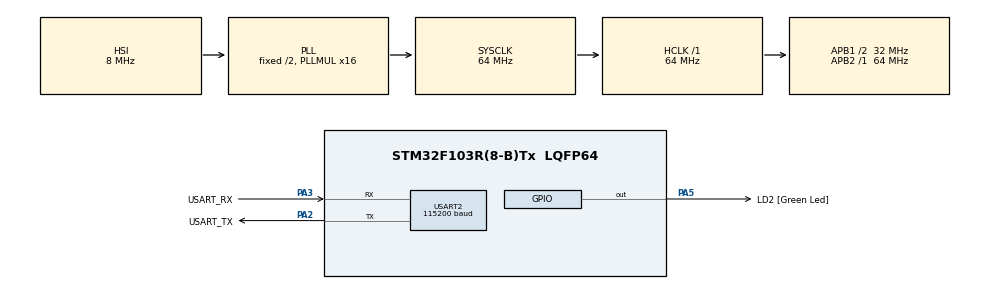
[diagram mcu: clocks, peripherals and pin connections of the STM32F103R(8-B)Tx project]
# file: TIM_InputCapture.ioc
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Mcu.Family=STM32F1
Mcu.Name=STM32F103R(8-B)Tx
Mcu.Package=LQFP64
NVIC.PriorityGroup=NVIC_PRIORITYGROUP_4
NVIC.TIM2_IRQn=true\:1\:0\:false\:false\:true\:true\:true\:true
PA0-WKUP.GPIO_Label=IC_IN
PA0-WKUP.GPIO_PuPd=GPIO_NOPULL
PA0-WKUP.Signal=S_TIM2_CH1_ETR
PA13.GPIO_Label=TMS
PA13.Mode=Serial_Wire
PA13.Signal=SYS_JTMS-SWDIO
PA14.GPIO_Label=TCK
PA14.Mode=Serial_Wire
PA14.Signal=SYS_JTCK-SWCLK
PA2.GPIO_Label=USART_TX
PA2.GPIO_Mode=GPIO_MODE_AF_PP
PA2.GPIO_PuPd=GPIO_NOPULL
PA2.GPIO_Speed=GPIO_SPEED_FREQ_LOW
PA2.Mode=Asynchronous
PA2.Signal=USART2_TX
PA3.GPIO_Label=USART_RX
PA3.GPIO_PuPd=GPIO_NOPULL
PA3.GPIO_Speed=GPIO_SPEED_FREQ_LOW
PA3.Mode=Asynchronous
PA3.Signal=USART2_RX
PA5.GPIO_Label=LD2 [Green Led]
PA5.GPIO_ModeDefaultOutputPP=GPIO_MODE_OUTPUT_PP
PA5.GPIO_PuPd=GPIO_NOPULL
PA5.GPIO_Speed=GPIO_SPEED_FREQ_LOW
PA5.Signal=GPIO_Output
PA6.GPIO_Label=TEST_PWM
PA6.GPIO_Speed=GPIO_SPEED_FREQ_HIGH
PA6.Signal=TIM3_CH1
PB3.GPIO_Label=SWO
PB3.Signal=SYS_JTDO-TRACESWO
PC14-OSC32_IN.Mode=LSE-External-Oscillator
PC14-OSC32_IN.Signal=RCC_OSC32_IN
PC15-OSC32_OUT.Mode=LSE-External-Oscillator
PC15-OSC32_OUT.Signal=RCC_OSC32_OUT
PD0-OSC_IN.Mode=HSE-External-Clock-Source
PD0-OSC_IN.Signal=RCC_OSC_IN
PD1-OSC_OUT.Mode=HSE-External-Clock-Source
PD1-OSC_OUT.Signal=RCC_OSC_OUT
ProjectManager.HeapSize=0x200
ProjectManager.StackSize=0x400
ProjectManager.TargetToolchain=STM32CubeIDE
RCC.AHBFreq_Value=64000000
RCC.APB1CLKDivider=RCC_HCLK_DIV2
RCC.APB1Freq_Value=32000000
RCC.APB1TimFreq_Value=64000000
RCC.APB2Freq_Value=64000000
RCC.APB2TimFreq_Value=64000000
RCC.HCLKFreq_Value=64000000
RCC.PLLMUL=RCC_PLL_MUL16
RCC.RTCClockSelection=RCC_RTCCLKSOURCE_LSE
RCC.SYSCLKFreq_VALUE=64000000
RCC.SYSCLKSource=RCC_SYSCLKSOURCE_PLLCLK
RCC.USBFreq_Value=64000000
TIM2.Channel=TIM_CHANNEL_1
TIM2.Period=65535
TIM2.Prescaler=63
TIM3.Channel-PWM Generation1 CH1=TIM_CHANNEL_1
TIM3.Period=9999
TIM3.Prescaler=63
TIM3.Pulse-PWM Generation1 CH1=5000
USART2.BaudRate=115200
USART2.VirtualMode=VM_ASYNC
board=NUCLEO-F103RB

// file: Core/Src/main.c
/* USER CODE BEGIN Header */
/**
 ******************************************************************************
 * @file           : main.c
 * @brief          : Main program body
 ******************************************************************************
 * @attention
 *
 * Copyright (c) 2026 STMicroelectronics.
 * All rights reserved.
 *
 * This software is licensed under terms that can be found in the LICENSE file
 * in the root directory of this software component.
 * If no LICENSE file comes with this software, it is provided AS-IS.
 *
 ******************************************************************************
 */
/**
 * 06_TIM_InputCapture  —  [계층: HAL]  TIM2 입력 캡처로 주파수 측정
 *
 * 동작
 *   - TIM3_CH1(PA6, 'D12')이 100Hz/50% PWM 테스트 신호를 출력한다.
 *   - TIM2_CH1(PA0, 'A0')이 상승 에지마다 CNT 값을 CCR1 에 래치(캡처)한다.
 *   - 연속된 두 캡처 값의 차 = 신호 주기(카운트) -> 주파수 계산 후 USART2(115200)로 0.5초마다 출력.
 *
 * 배선: PA6(D12) ---- 점퍼선 ---- PA0(A0)   (다른 신호를 측정하려면 PA0 에 연결)
 *
 * 측정 범위 계산
 *   TIM2 카운터 클럭 = 64MHz/64 = 1MHz (1us 분해능), 카운터 16비트(ARR=0xFFFF)
 *   최저 측정 주파수 = 1MHz/65536 = 약 15.3Hz,  주기 차 계산은 uint16_t 뺄셈으로 오버플로 1회를 자동 처리
 *
 * ISR vs 콜백
 *   TIM2_IRQHandler (stm32f1xx_it.c, 진짜 ISR) -> HAL_TIM_IRQHandler()
 *     -> HAL_TIM_IC_CaptureCallback() (이 파일)  : SR.CC1IF 발생 시 호출, ISR 문맥이므로 짧게 처리
 */
/* USER CODE END Header */
#include "main.h"

/* USER CODE BEGIN Includes */
#include <stdio.h>
#include <string.h>
/* USER CODE END Includes */

TIM_HandleTypeDef htim2;     /* 입력 캡처 */
TIM_HandleTypeDef htim3;     /* 테스트용 PWM */
UART_HandleTypeDef huart2;

/* USER CODE BEGIN PV */
static volatile uint16_t period_ticks;   /* 콜백에서 계산한 마지막 주기 [us] */
static volatile uint8_t  have_sample;    /* 마지막 출력 이후 새 캡처가 있었는가 */
static uint16_t last_capture;
static uint8_t  first_edge = 1;
/* USER CODE END PV */

void SystemClock_Config(void);
static void MX_GPIO_Init(void);
static void MX_TIM2_Init(void);
static void MX_TIM3_Init(void);
static void MX_USART2_UART_Init(void);

int main(void)
{

  /* USER CODE BEGIN 1 */
  char msg[64];
  /* USER CODE END 1 */

  /* MCU Configuration--------------------------------------------------------*/

  /* Reset of all peripherals, Initializes the Flash interface and the Systick. */
  HAL_Init();

  /* Configure the system clock */
  SystemClock_Config();

  /* Initialize all configured peripherals */
  MX_GPIO_Init();
  MX_TIM2_Init();
  MX_TIM3_Init();
  MX_USART2_UART_Init();
  /* USER CODE BEGIN 2 */
  /* TIM3_CH1 = PA6 테스트 PWM 시작: CCER.CC1E=1, CR1.CEN=1 */
  if (HAL_TIM_PWM_Start(&htim3, TIM_CHANNEL_1) != HAL_OK) Error_Handler();

  /* TIM2_CH1 입력 캡처 시작: DIER.CC1IE=1, CCER.CC1E=1, CR1.CEN=1 */
  if (HAL_TIM_IC_Start_IT(&htim2, TIM_CHANNEL_1) != HAL_OK) Error_Handler();
  /* USER CODE END 2 */

  /* Infinite loop */
  while (1)
  {

    /* USER CODE BEGIN 3 */
    HAL_Delay(500);

    /* ISR 과 공유하는 변수를 일관되게 복사하기 위해 잠깐 인터럽트를 막는다 */
    __disable_irq();
    uint16_t p = period_ticks;
    uint8_t ok = have_sample;
    have_sample = 0;
    __enable_irq();

    int n;
    if (ok && p != 0)
        n = snprintf(msg, sizeof msg, "period=%u us  freq=%lu Hz\r\n", (unsigned)p, (unsigned long)(1000000UL / p));
    else
        n = snprintf(msg, sizeof msg, "no signal on PA0\r\n");
    HAL_UART_Transmit(&huart2, (uint8_t *)msg, (uint16_t)n, 100);
  }
  /* USER CODE END 3 */
}

void SystemClock_Config(void)
{
  RCC_OscInitTypeDef RCC_OscInitStruct = {0};
  RCC_ClkInitTypeDef RCC_ClkInitStruct = {0};

  /** Initializes the RCC Oscillators according to the specified parameters
  * in the RCC_OscInitTypeDef structure.
  */
  RCC_OscInitStruct.OscillatorType = RCC_OSCILLATORTYPE_HSI;
  RCC_OscInitStruct.HSIState = RCC_HSI_ON;
  RCC_OscInitStruct.HSICalibrationValue = RCC_HSICALIBRATION_DEFAULT;
  RCC_OscInitStruct.PLL.PLLState = RCC_PLL_ON;
  RCC_OscInitStruct.PLL.PLLSource = RCC_PLLSOURCE_HSI_DIV2;
  RCC_OscInitStruct.PLL.PLLMUL = RCC_PLL_MUL16;
  if (HAL_RCC_OscConfig(&RCC_OscInitStruct) != HAL_OK)
  {
    Error_Handler();
  }

  /** Initializes the CPU, AHB and APB buses clocks
  */
  RCC_ClkInitStruct.ClockType = RCC_CLOCKTYPE_HCLK|RCC_CLOCKTYPE_SYSCLK
                              |RCC_CLOCKTYPE_PCLK1|RCC_CLOCKTYPE_PCLK2;
  RCC_ClkInitStruct.SYSCLKSource = RCC_SYSCLKSOURCE_PLLCLK;
  RCC_ClkInitStruct.AHBCLKDivider = RCC_SYSCLK_DIV1;
  RCC_ClkInitStruct.APB1CLKDivider = RCC_HCLK_DIV2;
  RCC_ClkInitStruct.APB2CLKDivider = RCC_HCLK_DIV1;

  if (HAL_RCC_ClockConfig(&RCC_ClkInitStruct, FLASH_LATENCY_2) != HAL_OK)
  {
    Error_Handler();
  }
}

static void MX_TIM2_Init(void)
{

  TIM_MasterConfigTypeDef sMasterConfig = {0};
  TIM_IC_InitTypeDef sConfigIC = {0};

  htim2.Instance = TIM2;
  htim2.Init.Prescaler = 63;
  htim2.Init.CounterMode = TIM_COUNTERMODE_UP;
  htim2.Init.Period = 65535;
  htim2.Init.ClockDivision = TIM_CLOCKDIVISION_DIV1;
  htim2.Init.AutoReloadPreload = TIM_AUTORELOAD_PRELOAD_DISABLE;
  if (HAL_TIM_IC_Init(&htim2) != HAL_OK)
  {
    Error_Handler();
  }
  sMasterConfig.MasterOutputTrigger = TIM_TRGO_RESET;
  sMasterConfig.MasterSlaveMode = TIM_MASTERSLAVEMODE_DISABLE;
  if (HAL_TIMEx_MasterConfigSynchronization(&htim2, &sMasterConfig) != HAL_OK)
  {
    Error_Handler();
  }
  sConfigIC.ICPolarity = TIM_INPUTCHANNELPOLARITY_RISING;
  sConfigIC.ICSelection = TIM_ICSELECTION_DIRECTTI;
  sConfigIC.ICPrescaler = TIM_ICPSC_DIV1;
  sConfigIC.ICFilter = 0;
  if (HAL_TIM_IC_ConfigChannel(&htim2, &sConfigIC, TIM_CHANNEL_1) != HAL_OK)
  {
    Error_Handler();
  }
  /* USER CODE BEGIN TIM2_Init 2 */
  /* TIM2_CH1 = PA0 : 상승 에지 입력 캡처 (CCMR1.CC1S=01 TI1 직접, CCER.CC1P=0 상승), 카운터 1MHz(1us), ARR=0xFFFF */
  /* USER CODE END TIM2_Init 2 */

}

static void MX_TIM3_Init(void)
{

  TIM_MasterConfigTypeDef sMasterConfig = {0};
  TIM_OC_InitTypeDef sConfigOC = {0};

  htim3.Instance = TIM3;
  htim3.Init.Prescaler = 63;
  htim3.Init.CounterMode = TIM_COUNTERMODE_UP;
  htim3.Init.Period = 9999;
  htim3.Init.ClockDivision = TIM_CLOCKDIVISION_DIV1;
  htim3.Init.AutoReloadPreload = TIM_AUTORELOAD_PRELOAD_DISABLE;
  if (HAL_TIM_PWM_Init(&htim3) != HAL_OK)
  {
    Error_Handler();
  }
  sMasterConfig.MasterOutputTrigger = TIM_TRGO_RESET;
  sMasterConfig.MasterSlaveMode = TIM_MASTERSLAVEMODE_DISABLE;
  if (HAL_TIMEx_MasterConfigSynchronization(&htim3, &sMasterConfig) != HAL_OK)
  {
    Error_Handler();
  }
  sConfigOC.OCMode = TIM_OCMODE_PWM1;
  sConfigOC.Pulse = 5000;
  sConfigOC.OCPolarity = TIM_OCPOLARITY_HIGH;
  sConfigOC.OCFastMode = TIM_OCFAST_DISABLE;
  if (HAL_TIM_PWM_ConfigChannel(&htim3, &sConfigOC, TIM_CHANNEL_1) != HAL_OK)
  {
    Error_Handler();
  }
  /* USER CODE BEGIN TIM3_Init 2 */
  /* TIM3_CH1 = PA6 : 100Hz, 듀티 50% (PSC=64-1 -> 1MHz, ARR=10000-1, CCR1=5000) */
  /* USER CODE END TIM3_Init 2 */
  HAL_TIM_MspPostInit(&htim3);

}

static void MX_USART2_UART_Init(void)
{

  huart2.Instance = USART2;
  huart2.Init.BaudRate = 115200;
  huart2.Init.WordLength = UART_WORDLENGTH_8B;
  huart2.Init.StopBits = UART_STOPBITS_1;
  huart2.Init.Parity = UART_PARITY_NONE;
  huart2.Init.Mode = UART_MODE_TX_RX;
  huart2.Init.HwFlowCtl = UART_HWCONTROL_NONE;
  huart2.Init.OverSampling = UART_OVERSAMPLING_16;
  if (HAL_UART_Init(&huart2) != HAL_OK)
  {
    Error_Handler();
  }

}

static void MX_GPIO_Init(void)
{
  GPIO_InitTypeDef GPIO_InitStruct = {0};

  /* GPIO Ports Clock Enable */
  __HAL_RCC_GPIOC_CLK_ENABLE();
  __HAL_RCC_GPIOD_CLK_ENABLE();
  __HAL_RCC_GPIOA_CLK_ENABLE();
  __HAL_RCC_GPIOB_CLK_ENABLE();

  /*Configure GPIO pin Output Level */
  HAL_GPIO_WritePin(LD2_GPIO_Port, LD2_Pin, GPIO_PIN_RESET);

  /*Configure GPIO pin : LD2_Pin */
  GPIO_InitStruct.Pin = LD2_Pin;
  GPIO_InitStruct.Mode = GPIO_MODE_OUTPUT_PP;
  GPIO_InitStruct.Pull = GPIO_NOPULL;
  GPIO_InitStruct.Speed = GPIO_SPEED_FREQ_LOW;
  HAL_GPIO_Init(LD2_GPIO_Port, &GPIO_InitStruct);

}

/* USER CODE BEGIN 4 */
/* ------------------------------------------------------------------------- */
/* HAL 콜백 (ISR 아님, HAL_TIM_IRQHandler 가 호출)                              */
/* ------------------------------------------------------------------------- */
void HAL_TIM_IC_CaptureCallback(TIM_HandleTypeDef *htim)
{
  if (htim->Instance == TIM2 && htim->Channel == HAL_TIM_ACTIVE_CHANNEL_1)
  {
    uint16_t now = (uint16_t)HAL_TIM_ReadCapturedValue(htim, TIM_CHANNEL_1);   /* TIM2->CCR1 */
    if (first_edge)
    {
      first_edge = 0;                        /* 첫 에지는 기준점일 뿐 */
    }
    else
    {
      period_ticks = (uint16_t)(now - last_capture);   /* 16비트 래핑 뺄셈 */
      have_sample = 1;
    }
    last_capture = now;
  }
}
/* USER CODE END 4 */

void Error_Handler(void)
{
  __disable_irq();
  while (1) {
  }
}
#ifdef USE_FULL_ASSERT
/**
  * @brief  Reports the name of the source file and the source line number
  *         where the assert_param error has occurred.
  * @param  file: pointer to the source file name
  * @param  line: assert_param error line source number
  * @retval None
  */
void assert_failed(uint8_t *file, uint32_t line)
{
  /* USER CODE BEGIN 6 */
  /* User can add his own implementation to report the file name and line
     number, ex: printf("Wrong parameters value: file %s on line %d\r\n", file,
     line) */
  /* USER CODE END 6 */
}
#endif /* USE_FULL_ASSERT */
